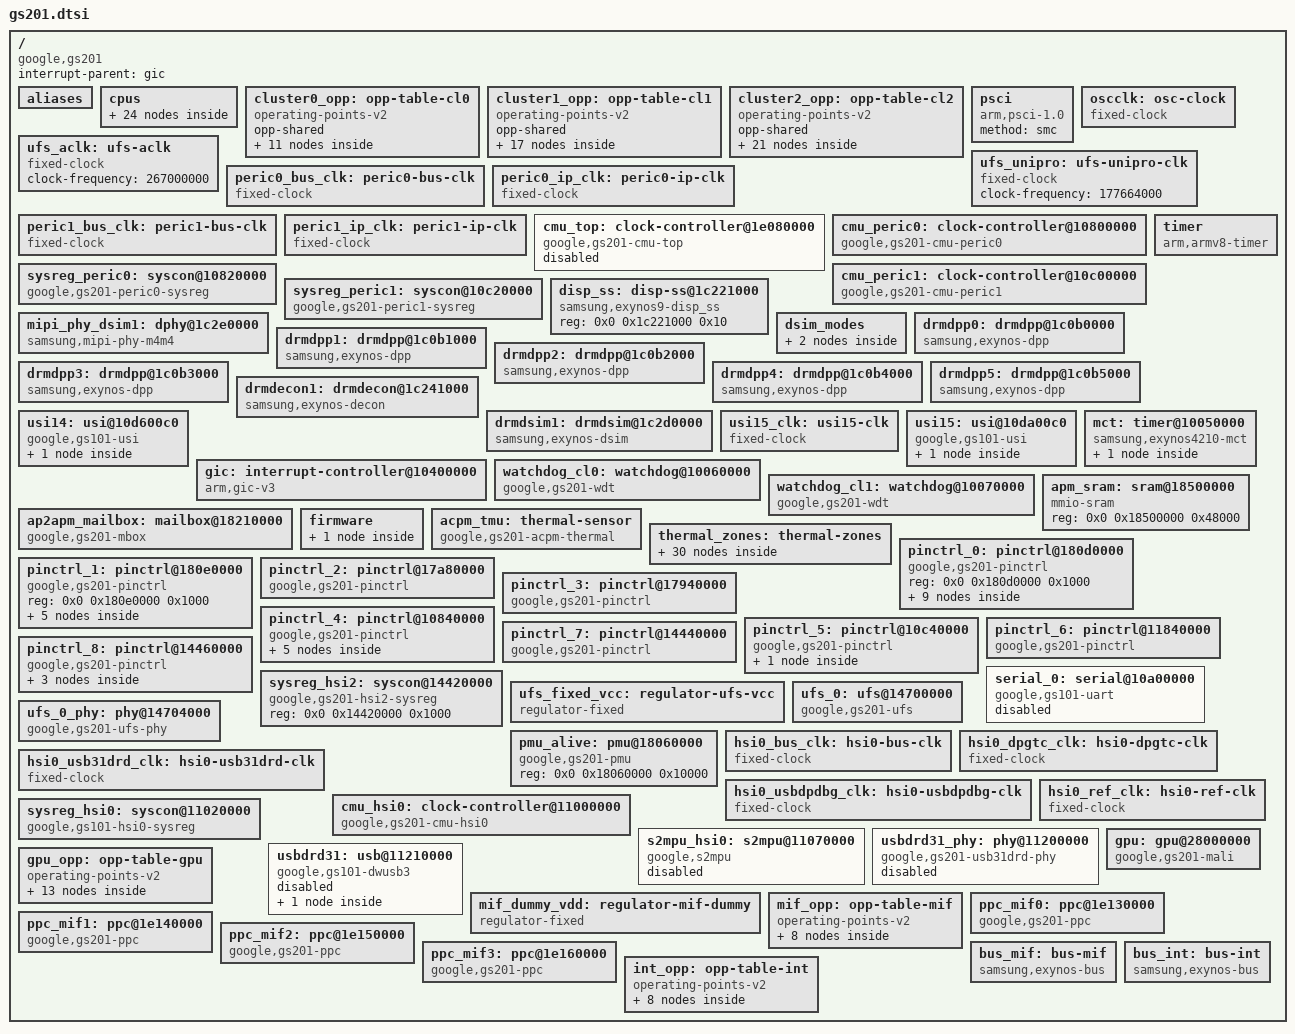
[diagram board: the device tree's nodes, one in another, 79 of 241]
// SPDX-License-Identifier: GPL-2.0-only
/*
 * Google GS201 (Tensor G2) SoC device tree source
 *
 * Copyright 2026 Google LLC
 *
 * Two non-obvious things about gs201:
 *
 * 1. BL31 firewalls EL1 CMU access UNLESS the kernel boots with
 *    `kvm-arm.mode=protected` (Makefile sets this). With pKVM disabled,
 *    direct readl of CMU_TOP @ 0x1e080000 aborts with synchronous external
 *    abort code 0x96000010. See memory/project_pkvm_cmu_unlock.md.
 *
 * 2. Even with CMU access unlocked, mainline `clk-gs101.c` is not
 *    register-layout compatible with gs201: many CMU_TOP and CMU_HSI2
 *    register offsets differ from gs101 (AOSP cal-if `cmucal-sfr.c` has
 *    the gs201-correct map; e.g. SHARED0_DIV4 is at 0x1930 on gs201 vs
 *    0x1908 on gs101, HSI2_BUS/MMC_CARD are swapped, etc.). Until a
 *    proper gs201 clock driver exists, UFS/peripheral clocks stay on
 *    fixed-rate stubs that report the bootloader-programmed rates.
 *    Hardware is already running at the right rate; the kernel just
 *    can't reprogram it without the correct offsets.
 */

#include <dt-bindings/clock/google,gs101.h>
#include <dt-bindings/clock/google,gs201-acpm.h>
#include <dt-bindings/gpio/gpio.h>
#include <dt-bindings/soc/samsung,exynos-usi.h>
#include <dt-bindings/interrupt-controller/arm-gic.h>
#include <dt-bindings/thermal/thermal.h>

/ {
	compatible = "google,gs201";
	interrupt-parent = <&gic>;
	#address-cells = <2>;
	#size-cells = <1>;

	aliases {
		pinctrl0 = &pinctrl_0;
		pinctrl1 = &pinctrl_1;
		pinctrl2 = &pinctrl_2;
		pinctrl3 = &pinctrl_3;
		pinctrl4 = &pinctrl_4;
		pinctrl5 = &pinctrl_5;
		pinctrl6 = &pinctrl_6;
		pinctrl7 = &pinctrl_7;
		pinctrl8 = &pinctrl_8;
		serial0  = &serial_0;
	};

	/* ------------------------------------------------------------------ */
	/* CPU topology                                                         */
	/* ------------------------------------------------------------------ */

	cpus {
		#address-cells = <2>;
		#size-cells = <0>;

		cpu-map {
			cluster0 {
				core0 { cpu = <&cpu0>; };
				core1 { cpu = <&cpu1>; };
				core2 { cpu = <&cpu2>; };
				core3 { cpu = <&cpu3>; };
			};
			cluster1 {
				core0 { cpu = <&cpu4>; };
				core1 { cpu = <&cpu5>; };
			};
			cluster2 {
				core0 { cpu = <&cpu6>; };
				core1 { cpu = <&cpu7>; };
			};
		};

		/* cluster0: ANANKE (Cortex-A55 derivative) */
		cpu0: cpu@0 {
			device_type = "cpu";
			compatible = "arm,cortex-a55";
			reg = <0x0 0x0000>;
			enable-method = "psci";
			cpu-idle-states = <&ananke_cpu_sleep>;
			capacity-dmips-mhz = <250>;
			dynamic-power-coefficient = <89>;
			operating-points-v2 = <&cluster0_opp>;
			clocks = <&acpm_ipc GS201_CLK_ACPM_DVFS_CPUCL0>;
			#cooling-cells = <2>;
		};
		cpu1: cpu@100 {
			device_type = "cpu";
			compatible = "arm,cortex-a55";
			reg = <0x0 0x0100>;
			enable-method = "psci";
			cpu-idle-states = <&ananke_cpu_sleep>;
			capacity-dmips-mhz = <250>;
			dynamic-power-coefficient = <89>;
			operating-points-v2 = <&cluster0_opp>;
			clocks = <&acpm_ipc GS201_CLK_ACPM_DVFS_CPUCL0>;
		};
		cpu2: cpu@200 {
			device_type = "cpu";
			compatible = "arm,cortex-a55";
			reg = <0x0 0x0200>;
			enable-method = "psci";
			cpu-idle-states = <&ananke_cpu_sleep>;
			capacity-dmips-mhz = <250>;
			dynamic-power-coefficient = <89>;
			operating-points-v2 = <&cluster0_opp>;
			clocks = <&acpm_ipc GS201_CLK_ACPM_DVFS_CPUCL0>;
		};
		cpu3: cpu@300 {
			device_type = "cpu";
			compatible = "arm,cortex-a55";
			reg = <0x0 0x0300>;
			enable-method = "psci";
			cpu-idle-states = <&ananke_cpu_sleep>;
			capacity-dmips-mhz = <250>;
			dynamic-power-coefficient = <89>;
			operating-points-v2 = <&cluster0_opp>;
			clocks = <&acpm_ipc GS201_CLK_ACPM_DVFS_CPUCL0>;
		};

		/* cluster1: HERCULES (Cortex-A78 derivative) */
		cpu4: cpu@400 {
			device_type = "cpu";
			compatible = "arm,cortex-a78";
			reg = <0x0 0x0400>;
			enable-method = "psci";
			cpu-idle-states = <&hercules_cpu_sleep>;
			capacity-dmips-mhz = <927>;
			dynamic-power-coefficient = <513>;
			operating-points-v2 = <&cluster1_opp>;
			clocks = <&acpm_ipc GS201_CLK_ACPM_DVFS_CPUCL1>;
			#cooling-cells = <2>;
		};
		cpu5: cpu@500 {
			device_type = "cpu";
			compatible = "arm,cortex-a78";
			reg = <0x0 0x0500>;
			enable-method = "psci";
			cpu-idle-states = <&hercules_cpu_sleep>;
			capacity-dmips-mhz = <927>;
			dynamic-power-coefficient = <513>;
			operating-points-v2 = <&cluster1_opp>;
			clocks = <&acpm_ipc GS201_CLK_ACPM_DVFS_CPUCL1>;
		};

		/* cluster2: HERA (Cortex-X1 derivative) */
		cpu6: cpu@600 {
			device_type = "cpu";
			compatible = "arm,cortex-x1";
			reg = <0x0 0x0600>;
			enable-method = "psci";
			cpu-idle-states = <&hera_cpu_sleep>;
			capacity-dmips-mhz = <1024>;
			dynamic-power-coefficient = <757>;
			operating-points-v2 = <&cluster2_opp>;
			clocks = <&acpm_ipc GS201_CLK_ACPM_DVFS_CPUCL2>;
			#cooling-cells = <2>;
		};
		cpu7: cpu@700 {
			device_type = "cpu";
			compatible = "arm,cortex-x1";
			reg = <0x0 0x0700>;
			enable-method = "psci";
			cpu-idle-states = <&hera_cpu_sleep>;
			capacity-dmips-mhz = <1024>;
			dynamic-power-coefficient = <757>;
			operating-points-v2 = <&cluster2_opp>;
			clocks = <&acpm_ipc GS201_CLK_ACPM_DVFS_CPUCL2>;
		};

		idle-states {
			entry-method = "arm,psci";

			ananke_cpu_sleep: ananke-cpu-sleep {
				compatible = "arm,idle-state";
				idle-state-name = "c2";
				arm,psci-suspend-param = <0x0010000>;
				entry-latency-us = <70>;
				exit-latency-us = <160>;
				min-residency-us = <2000>;
			};

			hercules_cpu_sleep: hercules-cpu-sleep {
				compatible = "arm,idle-state";
				idle-state-name = "c2";
				arm,psci-suspend-param = <0x0010000>;
				entry-latency-us = <150>;
				exit-latency-us = <190>;
				min-residency-us = <2500>;
			};

			hera_cpu_sleep: hera-cpu-sleep {
				compatible = "arm,idle-state";
				idle-state-name = "c2";
				arm,psci-suspend-param = <0x0010000>;
				entry-latency-us = <235>;
				exit-latency-us = <220>;
				min-residency-us = <3500>;
			};
		};
	};

	/* CPU OPP tables — frequencies sourced from Android DVFS tables */
	cluster0_opp: opp-table-cl0 {
		compatible = "operating-points-v2";
		opp-shared;
		opp-300000000  { opp-hz = /bits/ 64 <300000000>; opp-microvolt = <600000>; };
		opp-574000000  { opp-hz = /bits/ 64 <574000000>; opp-microvolt = <644000>; };
		opp-738000000  { opp-hz = /bits/ 64 <738000000>; opp-microvolt = <671000>; };
		opp-930000000  { opp-hz = /bits/ 64 <930000000>; opp-microvolt = <702000>; };
		opp-1066000000 { opp-hz = /bits/ 64 <1066000000>; opp-microvolt = <724000>; };
		opp-1197000000 { opp-hz = /bits/ 64 <1197000000>; opp-microvolt = <745000>; };
		opp-1328000000 { opp-hz = /bits/ 64 <1328000000>; opp-microvolt = <767000>; };
		opp-1459000000 { opp-hz = /bits/ 64 <1459000000>; opp-microvolt = <788000>; };
		opp-1574000000 { opp-hz = /bits/ 64 <1574000000>; opp-microvolt = <807000>; };
		opp-1746000000 { opp-hz = /bits/ 64 <1746000000>; opp-microvolt = <835000>; };
		opp-1836000000 { opp-hz = /bits/ 64 <1836000000>; opp-microvolt = <850000>; };
	};

	cluster1_opp: opp-table-cl1 {
		compatible = "operating-points-v2";
		opp-shared;
		opp-400000000  { opp-hz = /bits/ 64 <400000000>; opp-microvolt = <600000>; };
		opp-553000000  { opp-hz = /bits/ 64 <553000000>; opp-microvolt = <631000>; };
		opp-696000000  { opp-hz = /bits/ 64 <696000000>; opp-microvolt = <660000>; };
		opp-852000000  { opp-hz = /bits/ 64 <852000000>; opp-microvolt = <692000>; };
		opp-984000000  { opp-hz = /bits/ 64 <984000000>; opp-microvolt = <719000>; };
		opp-1106000000 { opp-hz = /bits/ 64 <1106000000>; opp-microvolt = <744000>; };
		opp-1197000000 { opp-hz = /bits/ 64 <1197000000>; opp-microvolt = <763000>; };
		opp-1328000000 { opp-hz = /bits/ 64 <1328000000>; opp-microvolt = <790000>; };
		opp-1459000000 { opp-hz = /bits/ 64 <1459000000>; opp-microvolt = <817000>; };
		opp-1606000000 { opp-hz = /bits/ 64 <1606000000>; opp-microvolt = <847000>; };
		opp-1737000000 { opp-hz = /bits/ 64 <1737000000>; opp-microvolt = <874000>; };
		opp-1836000000 { opp-hz = /bits/ 64 <1836000000>; opp-microvolt = <894000>; };
		opp-1950000000 { opp-hz = /bits/ 64 <1950000000>; opp-microvolt = <918000>; };
		opp-2048000000 { opp-hz = /bits/ 64 <2048000000>; opp-microvolt = <938000>; };
		opp-2130000000 { opp-hz = /bits/ 64 <2130000000>; opp-microvolt = <955000>; };
		opp-2253000000 { opp-hz = /bits/ 64 <2253000000>; opp-microvolt = <980000>; };
		opp-2348000000 { opp-hz = /bits/ 64 <2348000000>; opp-microvolt = <1000000>; };
	};

	cluster2_opp: opp-table-cl2 {
		compatible = "operating-points-v2";
		opp-shared;
		opp-500000000  { opp-hz = /bits/ 64 <500000000>; opp-microvolt = <650000>; };
		opp-851000000  { opp-hz = /bits/ 64 <851000000>; opp-microvolt = <709000>; };
		opp-955000000  { opp-hz = /bits/ 64 <955000000>; opp-microvolt = <727000>; };
		opp-1098000000 { opp-hz = /bits/ 64 <1098000000>; opp-microvolt = <751000>; };
		opp-1197000000 { opp-hz = /bits/ 64 <1197000000>; opp-microvolt = <768000>; };
		opp-1328000000 { opp-hz = /bits/ 64 <1328000000>; opp-microvolt = <790000>; };
		opp-1459000000 { opp-hz = /bits/ 64 <1459000000>; opp-microvolt = <813000>; };
		opp-1557000000 { opp-hz = /bits/ 64 <1557000000>; opp-microvolt = <829000>; };
		opp-1647000000 { opp-hz = /bits/ 64 <1647000000>; opp-microvolt = <845000>; };
		opp-1745000000 { opp-hz = /bits/ 64 <1745000000>; opp-microvolt = <861000>; };
		opp-1836000000 { opp-hz = /bits/ 64 <1836000000>; opp-microvolt = <877000>; };
		opp-1950000000 { opp-hz = /bits/ 64 <1950000000>; opp-microvolt = <896000>; };
		opp-2048000000 { opp-hz = /bits/ 64 <2048000000>; opp-microvolt = <913000>; };
		opp-2130000000 { opp-hz = /bits/ 64 <2130000000>; opp-microvolt = <927000>; };
		opp-2253000000 { opp-hz = /bits/ 64 <2253000000>; opp-microvolt = <948000>; };
		opp-2348000000 { opp-hz = /bits/ 64 <2348000000>; opp-microvolt = <964000>; };
		opp-2500000000 { opp-hz = /bits/ 64 <2500000000>; opp-microvolt = <990000>; };
		opp-2630000000 { opp-hz = /bits/ 64 <2630000000>; opp-microvolt = <1012000>; };
		opp-2704000000 { opp-hz = /bits/ 64 <2704000000>; opp-microvolt = <1025000>; };
		opp-2802000000 { opp-hz = /bits/ 64 <2802000000>; opp-microvolt = <1041000>; };
		opp-2850000000 { opp-hz = /bits/ 64 <2850000000>; opp-microvolt = <1050000>; };
	};

	/* ------------------------------------------------------------------ */
	/* System                                                               */
	/* ------------------------------------------------------------------ */

	psci {
		compatible = "arm,psci-1.0";
		method = "smc";
	};

	/* 24.576 MHz crystal — primary oscillator for the SoC */
	oscclk: osc-clock {
		compatible = "fixed-clock";
		#clock-cells = <0>;
		clock-frequency = <24576000>;
		clock-output-names = "oscclk";
	};

	/*
	 * Fixed-rate stubs for UFS — see top-of-file note about gs201
	 * CMU register offsets being incompatible with mainline clk-gs101.
	 * Rates back-computed from raw CMU_TOP register reads on a real
	 * boot using gs201-correct offsets (see git history for the probe):
	 *
	 *   PLL_CON3_PLL_SHARED0 = 0xa15b0400
	 *     → M=347, P=4, S=0 → 24.576MHz * 347/4/1 = 2,131,968,000 Hz
	 *   shared0_div4 = 2131968000 / 4 = 532,992,000 Hz
	 *   MUX_HSI2_UFS_EMBD = 1 (selects shared0_div4)
	 *   DIV_HSI2_UFS_EMBD = 2 (divides by 3)
	 *     → mclk_rate = 532992000 / 3 = 177,664,000 Hz
	 *
	 * ufs_aclk's actual rate would come from HSI2_NOC (gs201's "BUS"
	 * divider, at offset 0x189c — different from gs101's 0x1898 which
	 * holds MMC_CARD on gs201). Not yet measured; leaving at the
	 * driver's PCLK_AVAIL_MAX as a known-in-range value.
	 */
	ufs_aclk: ufs-aclk {
		compatible = "fixed-clock";
		#clock-cells = <0>;
		clock-frequency = <267000000>;
	};

	ufs_unipro: ufs-unipro-clk {
		compatible = "fixed-clock";
		#clock-cells = <0>;
		clock-frequency = <177664000>;
	};

	/*
	 * cmu_peric0 input-clock stubs. The mainline clk-gs101.c CMU_TOP
	 * driver isn't validated for gs201 yet (cmu_top is left disabled
	 * below), so cmu_peric0 can't get its bus/ip parents from there.
	 * Provide them as fixed-clocks at the rates AOSP cal-if reports
	 * for felix at runtime:
	 *
	 *   peric0_bus_clk @ 200 MHz — VDOUT_CMU_PERIC0_NOC target rate
	 *                              from cmucal-vclk.c.
	 *   peric0_ip_clk  @ 400 MHz — back-derived: AOSP says
	 *                              VCLK_DIV_CLK_PERIC0_USI0_UART
	 *                              = 200 MHz with the cmu_peric0
	 *                              divider at value 1 (divide by 2),
	 *                              so the user-mux output (= IP) is
	 *                              400 MHz.
	 *
	 * If samsung_tty later reports a base_baud that doesn't match
	 * 115200 cleanly, the actual IP rate is the first thing to recheck
	 * (read the cmu_peric0 USI0_UART divider register at offset 0x1808
	 * over /dev/mem, divide 400 MHz by (DIV+1) and compare to AOSP).
	 */
	peric0_bus_clk: peric0-bus-clk {
		compatible = "fixed-clock";
		#clock-cells = <0>;
		clock-frequency = <200000000>;
		clock-output-names = "peric0_bus";
	};

	peric0_ip_clk: peric0-ip-clk {
		compatible = "fixed-clock";
		#clock-cells = <0>;
		clock-frequency = <400000000>;
		clock-output-names = "peric0_ip";
	};

	/*
	 * PERIC1 bus/ip stubs — same rationale as peric0 above. cmu_top is
	 * disabled (SError on gs201's divider map), so cmu_peric1 can't pull
	 * its bus/ip parents from CLK_DOUT_CMU_PERIC1_* there; feed it the
	 * bootloader-programmed fixed rates instead. PERIC1 hosts USI14 (the
	 * felix MAX77759 PMIC/charger i2c bus, hsi2c@10d60000).
	 */
	peric1_bus_clk: peric1-bus-clk {
		compatible = "fixed-clock";
		#clock-cells = <0>;
		clock-frequency = <200000000>;
		clock-output-names = "peric1_bus";
	};

	peric1_ip_clk: peric1-ip-clk {
		compatible = "fixed-clock";
		#clock-cells = <0>;
		clock-frequency = <400000000>;
		clock-output-names = "peric1_ip";
	};

	/* ------------------------------------------------------------------ */
	/* CMU clock controllers                                                */
	/* ------------------------------------------------------------------ */

	/*
	 * Top-level CMU. clk-gs101.c declares `google,gs201-cmu-top` and uses
	 * the gs201-specific `top_cmu_info_gs201` rate table (gs201's PLL/MUX
	 * register offsets aren't byte-identical to gs101's — see gs201.dtsi
	 * top-of-file note). Probed via late_initcall so the EL1 reads happen
	 * after pKVM unlocks BL31's CMU firewall (project_pkvm_cmu_unlock.md).
	 */
	cmu_top: clock-controller@1e080000 {
		compatible = "google,gs201-cmu-top";
		reg = <0x0 0x1e080000 0x10000>;
		#clock-cells = <1>;
		clocks = <&oscclk>;
		clock-names = "oscclk";
		/*
		 * Disabled. Mainline clk-gs101.c advertises a
		 * `google,gs201-cmu-top` compat but reuses the gs101 register
		 * map. Empirically (2026-05-03 boot test) that map has at
		 * least one divider register at an offset gs201 doesn't
		 * implement: probe panics with `Asynchronous SError Interrupt`
		 * inside `clk_divider_recalc_rate` shortly after a benign
		 * "Unable to get CMU sysreg" warning. Re-enabling requires
		 * either a gs201-specific divider/mux table in clk-gs101.c
		 * (cross-referenced against AOSP cal-if cmucal-sfr.c offsets)
		 * or a brand new clk-gs201.c sibling driver.
		 */
		status = "disabled";
	};

	/*
	 * PERIC0 CMU — supplies clocks to USI0 UART (ttySAC0), I2C/SPI/I3C
	 * masters in the PERIC0 domain, GPIO/sysreg PCLKs, etc. Driver shares
	 * `peric0_cmu_info` with the gs101 variant; if a future investigation
	 * shows gs201's PERIC0 register layout differs from gs101's, this
	 * node will need to fall back to a fixed-clock stub for clk_uart_baud0
	 * until a gs201-specific rate table is written.
	 */
	cmu_peric0: clock-controller@10800000 {
		compatible = "google,gs201-cmu-peric0";
		reg = <0x0 0x10800000 0x10000>;
		#clock-cells = <1>;
		clocks = <&oscclk>, <&peric0_bus_clk>, <&peric0_ip_clk>;
		clock-names = "oscclk", "bus", "ip";
		samsung,sysreg = <&sysreg_peric0>;
	};

	sysreg_peric0: syscon@10820000 {
		compatible = "google,gs201-peric0-sysreg", "syscon";
		reg = <0x0 0x10820000 0x10000>;
		clocks = <&cmu_peric0 CLK_GOUT_PERIC0_SYSREG_PERIC0_PCLK>;
	};

	/*
	 * PERIC1 CMU + sysreg — clk-gs101.c advertises `google,gs201-cmu-peric1`
	 * and has the full PERIC1 mux/div/gate table. Same fixed-stub parent
	 * trick as cmu_peric0 (cmu_top is disabled). Supplies USI14 (hsi2c@10d60000).
	 */
	cmu_peric1: clock-controller@10c00000 {
		compatible = "google,gs201-cmu-peric1";
		reg = <0x0 0x10c00000 0x10000>;
		#clock-cells = <1>;
		clocks = <&oscclk>, <&peric1_bus_clk>, <&peric1_ip_clk>;
		clock-names = "oscclk", "bus", "ip";
		samsung,sysreg = <&sysreg_peric1>;
		/*
		 * USI13 (hsi2c@10d60000) clock fix. Its "_usi_user" mux selects
		 * { oscclk, dout_cmu_peric1_ip }; the latter comes from cmu_top,
		 * which is disabled on gs201, so the mux sits at rate 0 and the
		 * hsi2c driver can't bind. Unlike PERIC0/UART, clk-gs101.c has no
		 * gs201 stub variant for the PERIC1 USIs, so re-parent the mux to
		 * oscclk (24.576 MHz — plenty for 100/400 kHz i2c) here.
		 */
		assigned-clocks = <&cmu_peric1 CLK_MOUT_PERIC1_USI13_USI_USER>;
		assigned-clock-parents = <&oscclk>;
	};

	sysreg_peric1: syscon@10c20000 {
		compatible = "google,gs201-peric1-sysreg", "syscon";
		reg = <0x0 0x10c20000 0x10000>;
		clocks = <&cmu_peric1 CLK_GOUT_PERIC1_SYSREG_PERIC1_PCLK>;
	};

	/*
	 * Display (DPU) — OUTER/cover panel path DECON1 -> DSIM1 -> ea8182-f10.
	 * Drives the grafted AOSP samsung DRM (drivers/gpu/drm/samsung-felix).
	 * decon/dsim clocks + power are managed by the CAL layer via ACPM/CMU
	 * (no DT clock phandles, no genpd) — same "bootloader gate + CAL" model
	 * the gs201 fuel-gauge/USI stubs use. sysmmu_dpu is absent on mainline
	 * so GEM uses CMA (no iommus). decon1/dsim1 stay status="disabled" until
	 * the ACPM/EL3 pd_dpu power-on and the DSIM D-PHY shim land — probing
	 * DECON MMIO on an unpowered domain external-aborts (headless hang).
	 */
	disp_ss: disp-ss@1c221000 {
		compatible = "samsung,exynos9-disp_ss";
		reg = <0x0 0x1c221000 0x10>;
		reg-names = "sys";
	};

	mipi_phy_dsim1: dphy@1c2e0000 {
		compatible = "samsung,mipi-phy-m4m4";
		isolation = <0x3eb8>;
		owner = <0>;		/* 0: DSI, 1: CSI */
		#phy-cells = <1>;
	};

	/*
	 * DSI PLL params keyed by mode-name. dsim_mode_valid() rejects any
	 * display mode (MODE_NOMODE) for which dsim_get_clock_mode() finds no
	 * matching entry here, so without this node the ea8182 1080x2092 modes
	 * are pruned and no modeset is possible. pmsk/hs-clk/esc-clk are the
	 * AOSP felix values (gs101-display-timing.dtsi 1080x2092). The driver
	 * prefix-matches "1080x2092" so this one entry covers @60 and @120.
	 */
	dsim_modes: dsim_modes {
		dsim-modes {
			mode_1080x2092 {
				mode-name = "1080x2092";
				pmsk = <
					0x2 0xEE 0x3 0xA155 /* p m s k */
					>;
				hs-clk = <730>;
				esc-clk = <20>;
			};
		};
	};

	drmdpp0: drmdpp@1c0b0000 {	/* L0 */
		compatible = "samsung,exynos-dpp";
		reg = <0x0 0x1c0b0000 0x1000>, <0x0 0x1c0d0000 0x1000>, <0x0 0x1c0e0000 0x1000>;
		reg-names = "dma", "dpp", "hdr";
		interrupts = <GIC_SPI 262 IRQ_TYPE_LEVEL_HIGH>, <GIC_SPI 271 IRQ_TYPE_LEVEL_HIGH>;
		interrupt-names = "dma", "dpp";
		attr = <0x50047>;
		port = <0>;
		scale_down = <1>;
		scale_up = <1>;
		dpp,id = <0>;
	};
	drmdpp1: drmdpp@1c0b1000 {	/* L1 */
		compatible = "samsung,exynos-dpp";
		reg = <0x0 0x1c0b1000 0x1000>, <0x0 0x1c0d1000 0x1000>, <0x0 0x1c0e1000 0x1000>;
		reg-names = "dma", "dpp", "hdr";
		interrupts = <GIC_SPI 263 IRQ_TYPE_LEVEL_HIGH>, <GIC_SPI 272 IRQ_TYPE_LEVEL_HIGH>;
		interrupt-names = "dma", "dpp";
		attr = <0x50047>;
		port = <0>;
		scale_down = <1>;
		scale_up = <1>;
		dpp,id = <1>;
	};
	drmdpp2: drmdpp@1c0b2000 {	/* L2 */
		compatible = "samsung,exynos-dpp";
		reg = <0x0 0x1c0b2000 0x1000>, <0x0 0x1c0d2000 0x1000>, <0x0 0x1c0e2000 0x1000>;
		reg-names = "dma", "dpp", "hdr";
		interrupts = <GIC_SPI 264 IRQ_TYPE_LEVEL_HIGH>, <GIC_SPI 273 IRQ_TYPE_LEVEL_HIGH>;
		interrupt-names = "dma", "dpp";
		attr = <0x50047>;
		port = <1>;
		scale_down = <1>;
		scale_up = <1>;
		dpp,id = <2>;
	};
	drmdpp3: drmdpp@1c0b3000 {	/* L3 */
		compatible = "samsung,exynos-dpp";
		reg = <0x0 0x1c0b3000 0x1000>, <0x0 0x1c0d3000 0x1000>, <0x0 0x1c0e3000 0x1000>;
		reg-names = "dma", "dpp", "hdr";
		interrupts = <GIC_SPI 265 IRQ_TYPE_LEVEL_HIGH>, <GIC_SPI 274 IRQ_TYPE_LEVEL_HIGH>;
		interrupt-names = "dma", "dpp";
		attr = <0x50047>;
		port = <1>;
		scale_down = <1>;
		scale_up = <1>;
		dpp,id = <3>;
	};
	drmdpp4: drmdpp@1c0b4000 {	/* L4 */
		compatible = "samsung,exynos-dpp";
		reg = <0x0 0x1c0b4000 0x1000>, <0x0 0x1c0d4000 0x1000>, <0x0 0x1c0e4000 0x1000>;
		reg-names = "dma", "dpp", "hdr";
		interrupts = <GIC_SPI 266 IRQ_TYPE_LEVEL_HIGH>, <GIC_SPI 275 IRQ_TYPE_LEVEL_HIGH>;
		interrupt-names = "dma", "dpp";
		attr = <0x50047>;
		port = <0>;
		scale_down = <1>;
		scale_up = <1>;
		dpp,id = <4>;
	};
	drmdpp5: drmdpp@1c0b5000 {	/* L5 */
		compatible = "samsung,exynos-dpp";
		reg = <0x0 0x1c0b5000 0x1000>, <0x0 0x1c0d5000 0x1000>, <0x0 0x1c0e5000 0x1000>;
		reg-names = "dma", "dpp", "hdr";
		interrupts = <GIC_SPI 267 IRQ_TYPE_LEVEL_HIGH>, <GIC_SPI 276 IRQ_TYPE_LEVEL_HIGH>;
		interrupt-names = "dma", "dpp";
		attr = <0x50047>;
		port = <1>;
		scale_down = <1>;
		scale_up = <1>;
		dpp,id = <5>;
	};

	drmdecon1: drmdecon@1c241000 {
		status = "okay";
		compatible = "samsung,exynos-decon";
		reg = <0x0 0x1c241000 0x6000>,	/* MAIN */
		      <0x0 0x1c250000 0x6000>,	/* WIN */
		      <0x0 0x1c260000 0x10000>,	/* SUB */
		      <0x0 0x1c280000 0x6000>,	/* WINCON */
		      <0x0 0x1c2b0000 0xf000>,	/* DQE1 */
		      <0x0 0x1c0bf000 0x1000>;	/* CGC_DMA */
		reg-names = "main", "win", "sub", "wincon", "dqe", "cgc-dma";
		decon,id = <1>;
		cgc-dma,id = <10>;
		interrupts = <GIC_SPI 246 IRQ_TYPE_LEVEL_HIGH>,		/* frame_start */
			     <GIC_SPI 245 IRQ_TYPE_LEVEL_HIGH>,		/* frame_done */
			     <GIC_SPI 244 IRQ_TYPE_LEVEL_HIGH>,		/* extra */
			     <GIC_SPI 243 IRQ_TYPE_LEVEL_HIGH>,		/* dimming_start */
			     <GIC_SPI 242 IRQ_TYPE_LEVEL_HIGH>,		/* dimming_end */
			     <GIC_SPI 261 IRQ_TYPE_LEVEL_HIGH>;		/* cgc-dma */
		interrupt-names = "frame_start", "frame_done", "extra",
				  "dimming_start", "dimming_end", "cgc-dma";
		max_win = <6>;
		ppc = <2>;
		ppc_rotator = <4>;
		ppc_scaler = <2>;
		delay_comp = <4>;
		delay_scaler = <3>;
		bus_width = <16>;
		bus_util = <65>;
		rot_util = <60>;
		dfs_lv_cnt = <7>;
		dfs_lv = <664000 533000 465000 400000 310000 267000 134000>;
		rd_en = <1>;
		rd_hi_thres = <0x800>;
		rd_lo_thres = <0x400>;
		rd_wait_cycle = <0x11>;
		dta_en = <1>;
		dta_hi_thres = <0x3200>;
		dta_lo_thres = <0x600>;
		dpps = <&drmdpp0 &drmdpp1 &drmdpp2 &drmdpp3 &drmdpp4 &drmdpp5>;
		/* DSI0(0x1), DSI1(0x2), VIDI(0x8) */
		connector = <0x1 0x2 0x8>;
	};

	drmdsim1: drmdsim@1c2d0000 {
		status = "okay";
		compatible = "samsung,exynos-dsim";
		reg = <0x0 0x1c2d0000 0x300>,	/* DSI */
		      <0x0 0x1c2e0900 0x700>,	/* M4M4S0 PHY */
		      <0x0 0x1c2e0000 0x100>;	/* M4M4S0 PHY BIAS */
		reg-names = "dsi", "dphy", "dphy-extra";
		dsim,id = <1>;
		interrupts = <GIC_SPI 251 IRQ_TYPE_LEVEL_HIGH>;
		interrupt-names = "dsim";
		phys = <&mipi_phy_dsim1 0>;
		phy-names = "dsim_dphy";
		dsim_mode = <&dsim_modes>;
		te_from = <1>;
		/* outer-panel TE (EINT) on gpp0-4; resolved via gpiod in the
		 * dsim driver so the decon takes HW command-mode trigger off
		 * the panel's tearing-effect line instead of sw_trigger. */
		te-gpios = <&gpp0 4 0>;
		pinctrl-names = "hw_te_on", "hw_te_off";
		pinctrl-0 = <&disp_te_sec_on>;
		pinctrl-1 = <&disp_te_sec_off>;
		#address-cells = <1>;
		#size-cells = <0>;
	};

	/*
	 * USI14 (PERIC1) in HS-I2C mode — the felix MAX77759 PMIC/charger/
	 * fuel-gauge/TCPC live on this bus (pmic@66, chrg@69, fg@36, tcpc@25).
	 * Same SoC block as gs101's usi13/hsi2c@10d60000; gs201 differs only in
	 * the GIC line (695) and the 2-cell soc addressing. Bring it up so we can
	 * reach the MAX77759 charger and enable its OTG VBUS boost (host-mode
	 * dongle networking).
	 */
	usi14: usi@10d600c0 {
		compatible = "google,gs101-usi", "samsung,exynos850-usi";
		reg = <0x0 0x10d600c0 0x20>;
		ranges;
		#address-cells = <2>;
		#size-cells = <1>;
		clocks = <&cmu_peric1 CLK_GOUT_PERIC1_PERIC1_TOP0_PCLK_6>,
			 <&cmu_peric1 CLK_GOUT_PERIC1_PERIC1_TOP0_IPCLK_6>;
		clock-names = "pclk", "ipclk";
		samsung,sysreg = <&sysreg_peric1 0x1014>;
		samsung,mode = <USI_MODE_I2C>;
		status = "okay";

		hsi2c14: i2c@10d60000 {
			compatible = "google,gs101-hsi2c",
				     "samsung,exynosautov9-hsi2c";
			reg = <0x0 0x10d60000 0xc0>;
			#address-cells = <1>;
			#size-cells = <0>;
			clocks = <&cmu_peric1 CLK_GOUT_PERIC1_PERIC1_TOP0_IPCLK_6>,
				 <&cmu_peric1 CLK_GOUT_PERIC1_PERIC1_TOP0_PCLK_6>;
			clock-names = "hsi2c", "hsi2c_pclk";
			interrupts = <GIC_SPI 695 IRQ_TYPE_LEVEL_HIGH>;
			/*
			 * No pinctrl-0: the gpp25-0/1 SDA/SCL pins are already in
			 * i2c alt-function from the bootloader (it talks to the
			 * MAX77759 on this bus), same as uart0 above. Declaring an
			 * hsi2c14_bus group would need all 26 gpp banks defined in
			 * order (samsung pinctrl matches bank subnodes positionally),
			 * which isn't worth it when the POR state already works.
			 */
			status = "okay";
		};
	};

		/*
		 * USI15 (PERIC1) in HS-I2C mode @ 10da0000 — felix's SECONDARY
		 * fuel gauge (the larger fold pack: max1720x@36 + 0x0b nvram) lives
		 * here, alongside the CS40L26 haptics, wireless charger and an
		 * EEPROM (not wired). This USI does NOT exist on gs101, so
		 * clk-gs101.c has no gs201 USI15 mux/gate model — feed the block a
		 * fixed ipclk/pclk stub instead. The bootloader leaves the CMU gate
		 * (GATE_PERIC1_TOP0_USI15_USI) enabled to reach the gauge at boot,
		 * and the cmdline's clk_ignore_unused keeps it that way, so the
		 * block stays clocked. GIC line 696, sysreg USI mode reg at peric1
		 * +0x18 (vs +0x14 for USI13), SDA/SCL on gpp24-0/1 (left in i2c
		 * alt-func by the bootloader, so no pinctrl-0).
		 */
		usi15_clk: usi15-clk {
			compatible = "fixed-clock";
			#clock-cells = <0>;
			clock-frequency = <200000000>;
			clock-output-names = "usi15_clk";
		};

		usi15: usi@10da00c0 {
			compatible = "google,gs101-usi", "samsung,exynos850-usi";
			reg = <0x0 0x10da00c0 0x20>;
			ranges;
			#address-cells = <2>;
			#size-cells = <1>;
			clocks = <&usi15_clk>, <&usi15_clk>;
			clock-names = "pclk", "ipclk";
			samsung,sysreg = <&sysreg_peric1 0x1018>;
			samsung,mode = <USI_MODE_I2C>;
			status = "okay";

			hsi2c15: i2c@10da0000 {
				compatible = "google,gs101-hsi2c",
					     "samsung,exynosautov9-hsi2c";
				reg = <0x0 0x10da0000 0xc0>;
				#address-cells = <1>;
				#size-cells = <0>;
				clocks = <&usi15_clk>, <&usi15_clk>;
				clock-names = "hsi2c", "hsi2c_pclk";
				interrupts = <GIC_SPI 696 IRQ_TYPE_LEVEL_HIGH>;
				status = "okay";
			};
		};

	/* ------------------------------------------------------------------ */
	/* Interrupt controller                                                 */
	/* ------------------------------------------------------------------ */

	gic: interrupt-controller@10400000 {
		compatible = "arm,gic-v3";
		#interrupt-cells = <3>;
		interrupt-controller;
		reg = <0x0 0x10400000 0x10000>,   /* GICD */
		      <0x0 0x10440000 0x100000>;  /* GICR × 8 */
		interrupts = <GIC_PPI 9 IRQ_TYPE_LEVEL_HIGH>;
	};

	/* ------------------------------------------------------------------ */
	/* Timers                                                               */
	/* ------------------------------------------------------------------ */

	timer {
		compatible = "arm,armv8-timer";
		interrupts = <GIC_PPI 13 (GIC_CPU_MASK_SIMPLE(8) | IRQ_TYPE_LEVEL_LOW)>,
			     <GIC_PPI 14 (GIC_CPU_MASK_SIMPLE(8) | IRQ_TYPE_LEVEL_LOW)>,
			     <GIC_PPI 11 (GIC_CPU_MASK_SIMPLE(8) | IRQ_TYPE_LEVEL_LOW)>,
			     <GIC_PPI 10 (GIC_CPU_MASK_SIMPLE(8) | IRQ_TYPE_LEVEL_LOW)>;
		clock-frequency = <24576000>;
	};

	mct: timer@10050000 {
		compatible = "samsung,exynos4210-mct";
		reg = <0x0 0x10050000 0x800>;
		interrupt-controller;
		#interrupt-cells = <1>;
		interrupt-parent = <&mct_map>;
		interrupts = <0>, <1>, <2>,  <3>,
			     <4>, <5>, <6>,  <7>,
			     <8>, <9>, <10>, <11>;
		clocks = <&oscclk>, <&oscclk>;
		clock-names = "fin_pll", "mct";

		mct_map: mct-map {
			#interrupt-cells = <1>;
			#address-cells = <0>;
			#size-cells = <0>;
			interrupt-map =
				<0  &gic 0 785 IRQ_TYPE_LEVEL_HIGH>,
				<1  &gic 0 786 IRQ_TYPE_LEVEL_HIGH>,
				<2  &gic 0 787 IRQ_TYPE_LEVEL_HIGH>,
				<3  &gic 0 788 IRQ_TYPE_LEVEL_HIGH>,
				<4  &gic 0 789 IRQ_TYPE_LEVEL_HIGH>,
				<5  &gic 0 790 IRQ_TYPE_LEVEL_HIGH>,
				<6  &gic 0 791 IRQ_TYPE_LEVEL_HIGH>,
				<7  &gic 0 792 IRQ_TYPE_LEVEL_HIGH>,
				<8  &gic 0 793 IRQ_TYPE_LEVEL_HIGH>,
				<9  &gic 0 794 IRQ_TYPE_LEVEL_HIGH>,
				<10 &gic 0 795 IRQ_TYPE_LEVEL_HIGH>,
				<11 &gic 0 796 IRQ_TYPE_LEVEL_HIGH>;
		};
	};

	/* ------------------------------------------------------------------ */
	/* Watchdog timers                                                      */
	/* ------------------------------------------------------------------ */

	watchdog_cl0: watchdog@10060000 {
		compatible = "google,gs201-wdt";
		reg = <0x0 0x10060000 0x100>;
		clocks = <&oscclk>;
		clock-names = "watchdog";
		interrupts = <GIC_SPI 797 IRQ_TYPE_LEVEL_HIGH>;
		samsung,syscon-phandle = <&pmu_alive>;
		samsung,cluster-index = <0>;
	};

	watchdog_cl1: watchdog@10070000 {
		compatible = "google,gs201-wdt";
		reg = <0x0 0x10070000 0x100>;
		clocks = <&oscclk>;
		clock-names = "watchdog";
		interrupts = <GIC_SPI 798 IRQ_TYPE_LEVEL_HIGH>;
		samsung,syscon-phandle = <&pmu_alive>;
		samsung,cluster-index = <1>;
	};

	/* ------------------------------------------------------------------ */
	/* ACPM — Always-on Power Management coprocessor                       */
	/* ------------------------------------------------------------------ */

	/*
	 * AP-to-APM mailbox — raises a doorbell interrupt to the ACPM
	 * coprocessor.  The ACPM IPC driver uses this via the mailbox
	 * framework.  "pclk" is the APM-domain peripheral clock; supply
	 * the oscclk stub until a GS201 ALIVE-CMU driver exists.
	 */
	ap2apm_mailbox: mailbox@18210000 {
		compatible = "google,gs201-mbox";
		reg = <0x0 0x18210000 0x1000>;
		clocks = <&oscclk>;
		clock-names = "pclk";
		interrupts = <GIC_SPI 78 IRQ_TYPE_LEVEL_HIGH>;
		#mbox-cells = <0>;
	};

	/*
	 * APM shared SRAM — 288 KiB window visible to both the AP and the
	 * ACPM coprocessor.  The ACPM IPC driver maps the channel descriptors
	 * and TX/RX buffers out of this region.
	 */
	apm_sram: sram@18500000 {
		compatible = "mmio-sram";
		reg = <0x0 0x18500000 0x48000>;
		#address-cells = <1>;
		#size-cells = <1>;
		ranges = <0 0x0 0x18500000 0x48000>;
	};

	firmware {
		/*
		 * ACPM IPC + DVFS clock provider.
		 * Exposes all DVFS-managed clocks (GPU, CPU clusters, MIF …)
		 * as a clock provider with #clock-cells = <1>.  Use the
		 * GS201_CLK_ACPM_DVFS_* constants from
		 * <dt-bindings/clock/google,gs201-acpm.h>.
		 */
		acpm_ipc: power-management {
			compatible = "google,gs201-acpm-ipc";
			#clock-cells = <1>;
			mboxes = <&ap2apm_mailbox>;
			shmem = <&apm_sram>;
		};
	};

	/*
	 * gs201 TMU is read over ACPM IPC (channel IPC_AP_TMU), not MMIO.
	 * The gs201_acpm_thermal driver registers these sensors; the cell in a
	 * thermal-zone's thermal-sensors phandle is the ACPM tz id:
	 *   0=BIG 1=MID 2=LITTLE 3=G3D 4=ISP 5=TPU 6=AUR 7=...
	 */
	acpm_tmu: thermal-sensor {
		compatible = "google,gs201-acpm-thermal";
		samsung,acpm-ipc = <&acpm_ipc>;
		samsung,tmu-channel = <9>;
		#thermal-sensor-cells = <1>;
	};

	thermal_zones: thermal-zones {
		/*
		 * Bring-up thermal management: the mainline port previously had
		 * no sensors at all, so the SoC heated unthrottled under load
		 * until a HW/PMIC cutoff hard-powered the device off. These
		 * zones give the thermal core temperatures to act on — passive
		 * trips throttle the matching CPU cluster / GPU DVFS, critical
		 * trips are a graceful-shutdown backstop below the HW cutoff.
		 */
		big-thermal {
			polling-delay-passive = <250>;
			polling-delay = <1000>;
			thermal-sensors = <&acpm_tmu 0>;
			sustainable-power = <2500>;
			trips {
				big_alert: alert {
					temperature = <90000>;
					hysteresis = <5000>;
					type = "passive";
				};
				big_crit: crit {
					temperature = <115000>;
					hysteresis = <0>;
					type = "critical";
				};
			};
			cooling-maps {
				map0 {
					trip = <&big_alert>;
					cooling-device = <&cpu6 THERMAL_NO_LIMIT THERMAL_NO_LIMIT>;
				};
			};
		};

		mid-thermal {
			polling-delay-passive = <250>;
			polling-delay = <1000>;
			thermal-sensors = <&acpm_tmu 1>;
			sustainable-power = <1500>;
			trips {
				mid_alert: alert {
					temperature = <90000>;
					hysteresis = <5000>;
					type = "passive";
				};
				mid_crit: crit {
					temperature = <115000>;
					hysteresis = <0>;
					type = "critical";
				};
			};
			cooling-maps {
				map0 {
					trip = <&mid_alert>;
					cooling-device = <&cpu4 THERMAL_NO_LIMIT THERMAL_NO_LIMIT>;
				};
			};
		};

		little-thermal {
			polling-delay-passive = <250>;
			polling-delay = <1000>;
			thermal-sensors = <&acpm_tmu 2>;
			sustainable-power = <800>;
			trips {
				little_alert: alert {
					temperature = <90000>;
					hysteresis = <5000>;
					type = "passive";
				};
				little_crit: crit {
					temperature = <115000>;
					hysteresis = <0>;
					type = "critical";
				};
			};
			cooling-maps {
				map0 {
					trip = <&little_alert>;
					cooling-device = <&cpu0 THERMAL_NO_LIMIT THERMAL_NO_LIMIT>;
				};
			};
		};

		g3d-thermal {
			polling-delay-passive = <250>;
			polling-delay = <1000>;
			thermal-sensors = <&acpm_tmu 3>;
			trips {
				g3d_alert: alert {
					temperature = <90000>;
					hysteresis = <5000>;
					type = "passive";
				};
				g3d_crit: crit {
					temperature = <115000>;
					hysteresis = <0>;
					type = "critical";
				};
			};
			cooling-maps {
				map0 {
					trip = <&g3d_alert>;
					cooling-device = <&gpu THERMAL_NO_LIMIT THERMAL_NO_LIMIT>;
				};
			};
		};

		/*
		 * On-die ISP (4) and TPU (5) TMU sensors. The ACPM TMU exposes
		 * 6 sensors (BIG/MID/LIT/GPU/ISP/TPU); these two are diagnostic-
		 * only - a headless felix drives neither block, but their power
		 * domains sit ungated (no genpd on mainline), so these zones
		 * instrument that idle-heat contribution and any future power-
		 * domain gating. No cooling-map: no DVFS knob throttles them.
		 * Critical trip kept as a graceful-shutdown backstop.
		 */
		isp-thermal {
			polling-delay-passive = <0>;
			polling-delay = <1000>;
			thermal-sensors = <&acpm_tmu 4>;
			trips {
				isp_crit: crit {
					temperature = <115000>;
					hysteresis = <0>;
					type = "critical";
				};
			};
		};

		tpu-thermal {
			polling-delay-passive = <0>;
			polling-delay = <1000>;
			thermal-sensors = <&acpm_tmu 5>;
			trips {
				tpu_crit: crit {
					temperature = <115000>;
					hysteresis = <0>;
					type = "critical";
				};
			};
		};
	};

	/* ------------------------------------------------------------------ */
	/* Pin controllers                                                      */
	/* ------------------------------------------------------------------ */

	/* 0: GPIO_ALIVE */
	pinctrl_0: pinctrl@180d0000 {
		compatible = "google,gs201-pinctrl";
		reg = <0x0 0x180d0000 0x1000>;
		wakeup-interrupt-controller {
			compatible = "google,gs101-wakeup-eint",
				     "samsung,exynos850-wakeup-eint",
				     "samsung,exynos7-wakeup-eint";
		};
		/*
		 * ALIVE EINTW banks. The samsung pinctrl driver needs a DT child
		 * node per bank (names match gs201_pin_alive in
		 * pinctrl-exynos-arm64.c) for the of_node/phandle; the old flat
		 * model tripped "Missing node for bank gpaN - invalid DTB" and
		 * left no <&gpa9> for the MAX77759 TCPC IRQ. Per-pin GIC SPIs are
		 * sequential from 0; gs201 gpa2 has 4 pins (gs101 had 5) so every
		 * later bank shifts down one vs gs101.
		 */
		gpa0: gpa0-gpio-bank {
			gpio-controller;
			#gpio-cells = <2>;
			interrupt-controller;
			#interrupt-cells = <2>;
			interrupt-parent = <&gic>;
			interrupts = <GIC_SPI 0 IRQ_TYPE_LEVEL_HIGH>,
				     <GIC_SPI 1 IRQ_TYPE_LEVEL_HIGH>,
				     <GIC_SPI 2 IRQ_TYPE_LEVEL_HIGH>,
				     <GIC_SPI 3 IRQ_TYPE_LEVEL_HIGH>,
				     <GIC_SPI 4 IRQ_TYPE_LEVEL_HIGH>,
				     <GIC_SPI 5 IRQ_TYPE_LEVEL_HIGH>,
				     <GIC_SPI 6 IRQ_TYPE_LEVEL_HIGH>,
				     <GIC_SPI 7 IRQ_TYPE_LEVEL_HIGH>;
		};

		gpa1: gpa1-gpio-bank {
			gpio-controller;
			#gpio-cells = <2>;
			interrupt-controller;
			#interrupt-cells = <2>;
			interrupt-parent = <&gic>;
			interrupts = <GIC_SPI 8 IRQ_TYPE_LEVEL_HIGH>,
				     <GIC_SPI 9 IRQ_TYPE_LEVEL_HIGH>,
				     <GIC_SPI 10 IRQ_TYPE_LEVEL_HIGH>,
				     <GIC_SPI 11 IRQ_TYPE_LEVEL_HIGH>,
				     <GIC_SPI 12 IRQ_TYPE_LEVEL_HIGH>,
				     <GIC_SPI 13 IRQ_TYPE_LEVEL_HIGH>,
				     <GIC_SPI 14 IRQ_TYPE_LEVEL_HIGH>;
		};

		gpa2: gpa2-gpio-bank {
			gpio-controller;
			#gpio-cells = <2>;
			interrupt-controller;
			#interrupt-cells = <2>;
			interrupt-parent = <&gic>;
			interrupts = <GIC_SPI 15 IRQ_TYPE_LEVEL_HIGH>,
				     <GIC_SPI 16 IRQ_TYPE_LEVEL_HIGH>,
				     <GIC_SPI 17 IRQ_TYPE_LEVEL_HIGH>,
				     <GIC_SPI 18 IRQ_TYPE_LEVEL_HIGH>;
		};

		gpa3: gpa3-gpio-bank {
			gpio-controller;
			#gpio-cells = <2>;
			interrupt-controller;
			#interrupt-cells = <2>;
			interrupt-parent = <&gic>;
			interrupts = <GIC_SPI 19 IRQ_TYPE_LEVEL_HIGH>,
				     <GIC_SPI 20 IRQ_TYPE_LEVEL_HIGH>,
				     <GIC_SPI 21 IRQ_TYPE_LEVEL_HIGH>,
				     <GIC_SPI 22 IRQ_TYPE_LEVEL_HIGH>;
		};

		gpa4: gpa4-gpio-bank {
			gpio-controller;
			#gpio-cells = <2>;
			interrupt-controller;
			#interrupt-cells = <2>;
			interrupt-parent = <&gic>;
			interrupts = <GIC_SPI 23 IRQ_TYPE_LEVEL_HIGH>,
				     <GIC_SPI 24 IRQ_TYPE_LEVEL_HIGH>,
				     <GIC_SPI 25 IRQ_TYPE_LEVEL_HIGH>,
				     <GIC_SPI 26 IRQ_TYPE_LEVEL_HIGH>;
		};

		gpa5: gpa5-gpio-bank {
			gpio-controller;
			#gpio-cells = <2>;
			interrupt-controller;
			#interrupt-cells = <2>;
			interrupt-parent = <&gic>;
			interrupts = <GIC_SPI 27 IRQ_TYPE_LEVEL_HIGH>,
				     <GIC_SPI 28 IRQ_TYPE_LEVEL_HIGH>,
				     <GIC_SPI 29 IRQ_TYPE_LEVEL_HIGH>,
				     <GIC_SPI 30 IRQ_TYPE_LEVEL_HIGH>,
				     <GIC_SPI 31 IRQ_TYPE_LEVEL_HIGH>,
				     <GIC_SPI 32 IRQ_TYPE_LEVEL_HIGH>,
				     <GIC_SPI 33 IRQ_TYPE_LEVEL_HIGH>;
		};

		gpa9: gpa9-gpio-bank {
			gpio-controller;
			#gpio-cells = <2>;
			interrupt-controller;
			#interrupt-cells = <2>;
			interrupt-parent = <&gic>;
			interrupts = <GIC_SPI 34 IRQ_TYPE_LEVEL_HIGH>,
				     <GIC_SPI 35 IRQ_TYPE_LEVEL_HIGH>,
				     <GIC_SPI 36 IRQ_TYPE_LEVEL_HIGH>,
				     <GIC_SPI 37 IRQ_TYPE_LEVEL_HIGH>,
				     <GIC_SPI 38 IRQ_TYPE_LEVEL_HIGH>,
				     <GIC_SPI 39 IRQ_TYPE_LEVEL_HIGH>,
				     <GIC_SPI 40 IRQ_TYPE_LEVEL_HIGH>,
				     <GIC_SPI 41 IRQ_TYPE_LEVEL_HIGH>;
		};

		gpa10: gpa10-gpio-bank {
			gpio-controller;
			#gpio-cells = <2>;
			interrupt-controller;
			#interrupt-cells = <2>;
			interrupt-parent = <&gic>;
			interrupts = <GIC_SPI 42 IRQ_TYPE_LEVEL_HIGH>,
				     <GIC_SPI 43 IRQ_TYPE_LEVEL_HIGH>;
		};
	};

	/* 1: GPIO_FAR_ALIVE */
	pinctrl_1: pinctrl@180e0000 {
		compatible = "google,gs201-pinctrl";
		reg = <0x0 0x180e0000 0x1000>;
		wakeup-interrupt-controller {
			compatible = "google,gs101-wakeup-eint",
				     "samsung,exynos850-wakeup-eint",
				     "samsung,exynos7-wakeup-eint";
		};
		gpa6: gpa6-gpio-bank {
			gpio-controller;
			#gpio-cells = <2>;
			interrupt-controller;
			#interrupt-cells = <2>;
			interrupt-parent = <&gic>;
			interrupts = <GIC_SPI 44 IRQ_TYPE_LEVEL_HIGH>,
				     <GIC_SPI 45 IRQ_TYPE_LEVEL_HIGH>,
				     <GIC_SPI 46 IRQ_TYPE_LEVEL_HIGH>,
				     <GIC_SPI 47 IRQ_TYPE_LEVEL_HIGH>,
				     <GIC_SPI 48 IRQ_TYPE_LEVEL_HIGH>,
				     <GIC_SPI 49 IRQ_TYPE_LEVEL_HIGH>,
				     <GIC_SPI 50 IRQ_TYPE_LEVEL_HIGH>,
				     <GIC_SPI 51 IRQ_TYPE_LEVEL_HIGH>;
		};

		gpa7: gpa7-gpio-bank {
			gpio-controller;
			#gpio-cells = <2>;
			interrupt-controller;
			#interrupt-cells = <2>;
			interrupt-parent = <&gic>;
			interrupts = <GIC_SPI 52 IRQ_TYPE_LEVEL_HIGH>,
				     <GIC_SPI 53 IRQ_TYPE_LEVEL_HIGH>,
				     <GIC_SPI 54 IRQ_TYPE_LEVEL_HIGH>,
				     <GIC_SPI 55 IRQ_TYPE_LEVEL_HIGH>;
		};

		gpa8: gpa8-gpio-bank {
			gpio-controller;
			#gpio-cells = <2>;
			interrupt-controller;
			#interrupt-cells = <2>;
			interrupt-parent = <&gic>;
			interrupts = <GIC_SPI 56 IRQ_TYPE_LEVEL_HIGH>,
				     <GIC_SPI 57 IRQ_TYPE_LEVEL_HIGH>,
				     <GIC_SPI 58 IRQ_TYPE_LEVEL_HIGH>,
				     <GIC_SPI 59 IRQ_TYPE_LEVEL_HIGH>,
				     <GIC_SPI 60 IRQ_TYPE_LEVEL_HIGH>,
				     <GIC_SPI 61 IRQ_TYPE_LEVEL_HIGH>,
				     <GIC_SPI 62 IRQ_TYPE_LEVEL_HIGH>,
				     <GIC_SPI 63 IRQ_TYPE_LEVEL_HIGH>;
		};

		gpa11: gpa11-gpio-bank {
			gpio-controller;
			#gpio-cells = <2>;
			interrupt-controller;
			#interrupt-cells = <2>;
			interrupt-parent = <&gic>;
			interrupts = <GIC_SPI 64 IRQ_TYPE_LEVEL_HIGH>,
				     <GIC_SPI 65 IRQ_TYPE_LEVEL_HIGH>;
		};
	};

	/* 2: GPIO_GSACORE (no interrupts to AP) */
	pinctrl_2: pinctrl@17a80000 {
		compatible = "google,gs201-pinctrl";
		reg = <0x0 0x17a80000 0x1000>;
		gpio-controller;
		#gpio-cells = <2>;
	};

	/* 3: GPIO_GSACTRL (no interrupts to AP) */
	pinctrl_3: pinctrl@17940000 {
		compatible = "google,gs201-pinctrl";
		reg = <0x0 0x17940000 0x1000>;
		gpio-controller;
		#gpio-cells = <2>;
	};

	/* 4: GPIO_PERIC0 */
	pinctrl_4: pinctrl@10840000 {
		compatible = "google,gs201-pinctrl";
		reg = <0x0 0x10840000 0x1000>;
		interrupts = <GIC_SPI 664 IRQ_TYPE_LEVEL_HIGH>;
		gpio-controller;
		#gpio-cells = <2>;
		interrupt-controller;
		#interrupt-cells = <2>;

		/*
		 * gpp0 bank — used for the UFS device's VCC enable pin
		 * (gpp0-1, see ufs_fixed_vcc below). The Samsung pinctrl
		 * driver requires explicit bank subnodes; without this,
		 * `<&gpp0 1 0>` won't resolve and ufs_fixed_vcc fails to
		 * register, leaving the UFS chip unpowered.
		 */
		gpp0: gpp0-gpio-bank {
			gpio-controller;
			#gpio-cells = <2>;
			interrupt-controller;
			#interrupt-cells = <2>;
		};


		/*
		 * Force gpp0-1 into GPIO output function so the
		 * ufs_fixed_vcc regulator can actually drive the UFS
		 * device's VCC enable line. Mainline Samsung pinctrl
		 * doesn't automatically switch the pin's alt-function
		 * when a consumer requests it as a GPIO; without an
		 * explicit pin-function = 0 entry, the bootloader's
		 * leftover function (or POR default) stays selected and
		 * gpio_set_value writes never reach the pad.
		 */
		ufs_vcc_en: ufs-vcc-en {
			samsung,pins = "gpp0-1";
			samsung,pin-function = <0>;
			samsung,pin-pud = <0>;
		};

		/*
		 * UART0 / USI0_UART pin function. Same pins, function, and
		 * pud setting as gs101 (gs101-pinctrl.dtsi:524) — felix's
		 * uart0 lives on gpp1-2/gpp1-3 with alt-function 2. The
		 * bootloader has typically already programmed these (UART
		 * works from earlycon without pinctrl), but declaring the
		 * state here lets samsung_tty's probe call pinctrl_select
		 * cleanly and survives any GPIO consumer that might toggle
		 * the bank.
		 */
		uart0_bus: uart0-bus-pins {
			samsung,pins = "gpp1-2", "gpp1-3";
			samsung,pin-function = <2>;
			samsung,pin-pud = <0>;
		};

		/*
		 * Outer-panel (dsim1) tearing-effect line. gpp0-4 carries the
		 * ea8182 panel's TE signal; pin-function 0xf selects the EINT
		 * alt-function so gpio_to_irq() yields the TE interrupt and the
		 * decon can HW-trigger command mode from it. The dsim driver
		 * selects hw_te_on at enable / hw_te_off at disable.
		 */
		disp_te_sec_on: disp-te-sec-on {
			samsung,pins = "gpp0-4";
			samsung,pin-function = <0xf>;
		};

		disp_te_sec_off: disp-te-sec-off {
			samsung,pins = "gpp0-4";
			samsung,pin-function = <0>;
		};
	};

	/* 5: GPIO_PERIC1 */
	pinctrl_5: pinctrl@10c40000 {
		compatible = "google,gs201-pinctrl";
		reg = <0x0 0x10c40000 0x1000>;
		interrupts = <GIC_SPI 683 IRQ_TYPE_LEVEL_HIGH>;
		gpio-controller;
		#gpio-cells = <2>;
		interrupt-controller;
		#interrupt-cells = <2>;

		/*
		 * gpp23 bank — the outer panel's reset line is gpp23-0
		 * (see gs201-felix.dts panel@0 reset-gpios). Like the gpp0
		 * UFS-VCC case above, the Samsung pinctrl driver needs an
		 * explicit bank subnode for `<&gpp23 0 ...>` to resolve;
		 * without it the panel's devm_gpiod_get("reset") fails and
		 * the ea8182 driver aborts probe.
		 */
		gpp23: gpp23-gpio-bank {
			gpio-controller;
			#gpio-cells = <2>;
			interrupt-controller;
			#interrupt-cells = <2>;
		};
	};

	/* 6: GPIO_HSI1 */
	pinctrl_6: pinctrl@11840000 {
		compatible = "google,gs201-pinctrl";
		reg = <0x0 0x11840000 0x1000>;
		interrupts = <GIC_SPI 387 IRQ_TYPE_LEVEL_HIGH>;
		gpio-controller;
		#gpio-cells = <2>;
		interrupt-controller;
		#interrupt-cells = <2>;
	};

	/* 7: GPIO_HSI2 */
	pinctrl_7: pinctrl@14440000 {
		compatible = "google,gs201-pinctrl";
		reg = <0x0 0x14440000 0x1000>;
		interrupts = <GIC_SPI 421 IRQ_TYPE_LEVEL_HIGH>;
		gpio-controller;
		#gpio-cells = <2>;
		interrupt-controller;
		#interrupt-cells = <2>;
	};

	/* 8: GPIO_HSI2UFS — split from HSI2 vs GS101 */
	pinctrl_8: pinctrl@14460000 {
		compatible = "google,gs201-pinctrl";
		reg = <0x0 0x14460000 0x1000>;
		interrupts = <GIC_SPI 422 IRQ_TYPE_LEVEL_HIGH>;
		gpio-controller;
		#gpio-cells = <2>;
		interrupt-controller;
		#interrupt-cells = <2>;

		/*
		 * gph3 bank (2 pins at offset 0x000) — the only bank under
		 * pinctrl_8. The gs201 pin-controller driver has the layout
		 * hardcoded (gs201_pin_hsi2ufs[] in pinctrl-exynos-arm64.c),
		 * but it still needs this subnode to exist so pin references
		 * like "gph3-0" in the pin-state nodes below can be resolved.
		 */
		gph3: gph3-gpio-bank {
			gpio-controller;
			#gpio-cells = <2>;
			interrupt-controller;
			#interrupt-cells = <2>;
		};

		/*
		 * UFS GPIO pin-mux states, consumed by ufs_0's pinctrl-0.
		 * These belong nested in their owning pin-controller — placing
		 * them at the root of the tree (as this file originally did)
		 * makes fw_devlink treat the phandle targets as supplier
		 * *devices* and defer ufs_0's probe forever waiting for a
		 * driver that will never bind to a pinctrl-state subnode.
		 */
		/*
		 * Both pins use pin-function = 2 (UFS host-controller alt
		 * function), not GPIO. With GPIO, the host controller's
		 * internal HCI_GPIO_OUT reset toggle (driven by
		 * exynos_ufs_dev_hw_reset()) never reaches the UFS device's
		 * RST_N pin, so the device can't respond to LINKSTARTUP and
		 * link startup fails 4× then aborts. Values match AOSP
		 * gs201-pinctrl.dtsi.
		 */
		ufs_rst_n: ufs-rst-n {
			samsung,pins = "gph3-1";
			samsung,pin-function = <2>;
			samsung,pin-pud = <0>;
			samsung,pin-con-pdn = <3>;
			samsung,pin-pud-pdn = <0>;
		};

		ufs_refclk_out: ufs-refclk-out {
			samsung,pins = "gph3-0";
			samsung,pin-function = <2>;
			samsung,pin-pud = <0>;
			samsung,pin-con-pdn = <3>;
			samsung,pin-pud-pdn = <0>;
		};
	};

	/* ------------------------------------------------------------------ */
	/* Serial console (UART0 / USI0_UART, PERIC0)                         */
	/* ------------------------------------------------------------------ */

	serial_0: serial@10a00000 {
		/*
		 * google,gs101-uart (NOT samsung,exynos850-uart) so the
		 * driver picks up gs101_serial_drv_data with iotype =
		 * UPIO_MEM32. gs201's UART register block requires
		 * 32-bit-aligned access — a byte write to UTXH (which
		 * is what samsung_tty's wr_reg() does under UPIO_MEM)
		 * raises an asynchronous SError that the kernel ultimately
		 * panics on inside console_unlock(). Earlycon already
		 * uses 32-bit access (cmdline: earlycon=exynos4210,
		 * mmio32,...), so it works regardless. Empirically
		 * verified on felix 2026-05-03.
		 */
		compatible = "google,gs101-uart";
		reg = <0x0 0x10a00000 0x100>;
		samsung,fifo-size = <256>;
		interrupts = <GIC_SPI 673 IRQ_TYPE_LEVEL_HIGH>;
		/*
		 * gs201 has no PERIC0_TOP1 cluster (gs101's TOP1 IPCLK_0 /
		 * PCLK_0 gates don't exist on gs201 hardware). Wire directly
		 * to the per-peripheral USI0_UART gate (CLK_GOUT_PERIC0_CLK_
		 * PERIC0_USI0_UART_CLK) and the cmu_peric0 USI0_UART divider
		 * (CLK_DOUT_PERIC0_USI0_UART) — both register at gs201's
		 * shifted offsets in peric0_cmu_info_gs201 (clk-gs101.c).
		 */
		clocks = <&cmu_peric0 CLK_GOUT_PERIC0_CLK_PERIC0_USI0_UART_CLK>,
			 <&cmu_peric0 CLK_DOUT_PERIC0_USI0_UART>;
		clock-names = "uart", "clk_uart_baud0";
		pinctrl-0 = <&uart0_bus>;
		pinctrl-names = "default";
		status = "disabled";
	};

	/* ------------------------------------------------------------------ */
	/* UFS storage (HSI2 subsystem)                                        */
	/* ------------------------------------------------------------------ */

	sysreg_hsi2: syscon@14420000 {
		compatible = "google,gs201-hsi2-sysreg", "syscon";
		reg = <0x0 0x14420000 0x1000>;
	};

	/*
	 * UFS device VCC enable. The KIOXIA THGJFGT1E45BAIPB's main power
	 * rail is gated by gpp0-1 on felix; the bootloader drives it high to
	 * talk to the device, then drops it during shutdown ("[I] [UFS]
	 * shutdown complete"). Without this regulator, the kernel's UFS
	 * driver sees a powered-down device — link startup completes (host
	 * PHY has independent power) but every NOP OUT response slot stays
	 * at 0 because the device chip isn't running. Matches AOSP's
	 * gs201-ufs.dtsi ufs_fixed_vcc.
	 */
	ufs_fixed_vcc: regulator-ufs-vcc {
		compatible = "regulator-fixed";
		regulator-name = "ufs-vcc";
		gpio = <&gpp0 1 GPIO_ACTIVE_HIGH>;
		enable-active-high;
		/*
		 * Deliberately omit regulator-boot-on. The bootloader's
		 * `[I] [UFS] shutdown complete` drops VCC before handing
		 * off, so when the kernel boots the rail is OFF. With
		 * regulator-boot-on, the framework would think it's
		 * already on and skip the GPIO drive when UFS calls
		 * regulator_enable. Without it, the framework runs the
		 * fixed-voltage enable path and gpiod_set_value actually
		 * drives gpp0-1 high.
		 *
		 * Power-on settling time. UFS device VCC needs to be
		 * stable before the host issues commands; without this
		 * the link comes up but NOP OUT can race the device's
		 * internal init.
		 */
		startup-delay-us = <2000>;
		pinctrl-names = "default";
		pinctrl-0 = <&ufs_vcc_en>;
	};

	ufs_0: ufs@14700000 {
		compatible = "google,gs201-ufs";
		reg = <0x0 0x14700000 0x200>,   /* HCI standard  */
		      <0x0 0x14701100 0x200>,   /* vendor HCI    */
		      <0x0 0x14780000 0xa000>,  /* UNIPRO        */
		      <0x0 0x14600000 0x100>;   /* UFS protector */
		reg-names = "hci", "vs_hci", "unipro", "ufsp";
		interrupts = <GIC_SPI 453 IRQ_TYPE_LEVEL_HIGH>;
		pinctrl-names = "default";
		pinctrl-0 = <&ufs_rst_n &ufs_refclk_out>;
		clocks = <&ufs_aclk>, <&ufs_unipro>, <&ufs_aclk>,
			 <&ufs_aclk>, <&ufs_aclk>,   <&ufs_aclk>;
		clock-names = "core_clk", "sclk_unipro_main", "fmp",
			      "aclk", "pclk", "sysreg";
		freq-table-hz = <0 0>, <0 0>, <0 0>, <0 0>, <0 0>, <0 0>;
		phys = <&ufs_0_phy>;
		phy-names = "ufs-phy";
		vcc-supply = <&ufs_fixed_vcc>;
		ufs,pmd-attr-lane = /bits/ 8 <2>;
		ufs,pmd-attr-gear = /bits/ 8 <4>;
		/*
		 * `dma-coherent` is required on gs201. exynos_ufs_parse_dt sets
		 * `iocc_val = iocc_mask` only when of_dma_is_coherent() is true;
		 * otherwise it sets iocc_val = 0, which causes
		 * exynos_ufs_shareability's regmap_update_bits(sysreg+0x710,
		 * mask=0x3, val=0) to actively CLEAR the bootloader's IOCC RD/WR
		 * Sharable bits (observed: bootloader 0x13 → kernel 0x10). With
		 * the bits cleared, the controller's AXI transactions are issued
		 * with Device-memory semantics, so its UPIU writes never reach
		 * CPU-visible DRAM (proven via magic-stamp test — controller fires
		 * UTRCS but the response slot stays at 0xAB through the entire
		 * transaction). Match AOSP's gs201-ufs.dtsi which has both
		 * `dma-coherent` and `ufs-iocc { val = <0x3>; }`.
		 */
		dma-coherent;
		samsung,sysreg = <&sysreg_hsi2 0x710>;
	};

	/* UFS PHY ref_clk is the 24.576 MHz SoC oscillator (gs101 uses the
	 * same here). The PHY init sequence in phy-gs101-ufs.c writes ~70
	 * magic register values calibrated for this reference frequency. */
	ufs_0_phy: phy@14704000 {
		compatible = "google,gs201-ufs-phy";
		reg = <0x0 0x14704000 0x3000>;
		reg-names = "phy-pma";
		clocks = <&oscclk>;
		clock-names = "ref_clk";
		samsung,pmu-syscon = <&pmu_alive>;
		#phy-cells = <0>;
	};

	/* UFS pin-mux states (ufs_rst_n, ufs_refclk_out) live inside pinctrl_8
	 * above — see the comment there for why they must not be at root. */

	/* ------------------------------------------------------------------ */
	/* PMU syscon (needed by UFS PHY and power domain drivers)             */
	/* ------------------------------------------------------------------ */

	/*
	 * Drop the "syscon" fallback compat: when both are present, the
	 * generic of_syscon driver registers a direct-MMIO regmap for the
	 * node and races/shadows the SMC-routed regmap that exynos-pmu.c
	 * installs via of_syscon_register_regmap(). With only
	 * "google,gs201-pmu" present (matching gs101.dtsi), exynos-pmu wins
	 * and syscon_regmap_lookup_by_phandle() returns the SMC regmap, so
	 * UFS PHY isolation writes to PMU_ALIVE+0x3ec8 go through BL31
	 * instead of aborting.
	 */
	pmu_alive: pmu@18060000 {
		compatible = "google,gs201-pmu";
		reg = <0x0 0x18060000 0x10000>;
	};

	/* ------------------------------------------------------------------ */
	/* USB 3.1 (HSI0 subsystem) — type-C port on the Pixel Fold           */
	/*                                                                    */
	/* Layout mirrors gs101.dtsi (Pixel 6) at 0x1100_0000 — gs201 reuses  */
	/* the same HSI0 register map per AOSP cal-if. Driver bindings:       */
	/*   - cmu_hsi0:    google,gs201-cmu-hsi0  (clk-gs101.c, gs201 entry  */
	/*                  shares hsi0_cmu_info).                            */
	/*   - sysreg_hsi0: google,gs101-hsi0-sysreg + syscon (no gs201       */
	/*                  variant; register layout is identical).           */
	/*   - usbdrd31_phy: google,gs101-usb31drd-phy (phy-exynos5-usbdrd).  */
	/*   - usbdrd31:     google,gs101-dwusb3 (dwc3-exynos.c).             */
	/*                                                                    */
	/* HSI0 user-mux input parents (bus / dpgtc / usb31drd / usbdpdbg):   */
	/* gs101 sources these from cmu_top dout outputs; gs201 leaves        */
	/* cmu_top disabled (clk_divider_recalc_rate panics on its rate       */
	/* table — see top-of-file note), so we feed cmu_hsi0 from fixed-rate */
	/* stubs at the AOSP-typical rates instead. Same workaround pattern   */
	/* as cmu_peric0 above. Rates may need refinement once cmu_top boots; */
	/* until then the user-muxes will land on whatever bootloader-       */
	/* programmed value matches one of these stubs.                       */
	/*                                                                    */
	/* Status = "disabled" on every node here. felix.dts (or a future    */
	/* board file) re-enables them when the board has the necessary      */
	/* regulators / TCPC / role-switch wiring up.                         */
	/* ------------------------------------------------------------------ */

	hsi0_bus_clk: hsi0-bus-clk {
		compatible = "fixed-clock";
		#clock-cells = <0>;
		clock-frequency = <400000000>;
		clock-output-names = "hsi0_bus";
	};

	hsi0_dpgtc_clk: hsi0-dpgtc-clk {
		compatible = "fixed-clock";
		#clock-cells = <0>;
		clock-frequency = <200000000>;
		clock-output-names = "hsi0_dpgtc";
	};

	hsi0_usb31drd_clk: hsi0-usb31drd-clk {
		compatible = "fixed-clock";
		#clock-cells = <0>;
		clock-frequency = <19200000>;
		clock-output-names = "hsi0_usb31drd";
	};

	hsi0_usbdpdbg_clk: hsi0-usbdpdbg-clk {
		compatible = "fixed-clock";
		#clock-cells = <0>;
		clock-frequency = <24576000>;
		clock-output-names = "hsi0_usbdpdbg";
	};

	/*
	 * USB PHY reference-clock rate stub. The mainline PHY driver checks
	 * `clk_get_rate("ref")` against a fixed allow-list (9.6/10/12/19.2/20/
	 * 24/26/50 MHz, strict equality). When fed via cmu_hsi0 the rate
	 * walks back through the user-mux/PLL chain — which on gs201 reads
	 * back the bootloader-programmed PLL (~614.4 MHz) because cmu_top
	 * stays disabled, and PHY probe rejects the rate with -EINVAL.
	 *
	 * Workaround: tell the driver "ref is 26 MHz" via a fixed-clock,
	 * matching the AOSP/cal-if rate that the gs101 clock name suffix
	 * `_REFCLK_26` already reflects. The actual REFCLK pin going into
	 * the PHY is driven by the bootloader-programmed cmu_hsi0 hardware,
	 * not this stub — the stub only feeds the kernel's rate accounting.
	 */
	hsi0_ref_clk: hsi0-ref-clk {
		compatible = "fixed-clock";
		#clock-cells = <0>;
		clock-frequency = <26000000>;
		clock-output-names = "hsi0_ref";
	};

	cmu_hsi0: clock-controller@11000000 {
		compatible = "google,gs201-cmu-hsi0";
		reg = <0x0 0x11000000 0x10000>;
		#clock-cells = <1>;
		clocks = <&oscclk>,
			 <&hsi0_bus_clk>,
			 <&hsi0_dpgtc_clk>,
			 <&hsi0_usb31drd_clk>,
			 <&hsi0_usbdpdbg_clk>;
		clock-names = "oscclk", "bus", "dpgtc", "usb31drd", "usbdpdbg";
		samsung,sysreg = <&sysreg_hsi0>;
	};

	sysreg_hsi0: syscon@11020000 {
		compatible = "google,gs101-hsi0-sysreg", "syscon";
		reg = <0x0 0x11020000 0x10000>;
		clocks = <&cmu_hsi0 CLK_GOUT_HSI0_SYSREG_HSI0_PCLK>;
	};

	/*
	 * gs201 PHY register layout differs from gs101 mainline expects:
	 *   - "phy" (UTMI registers, LINKCTRL at +0x04, UTMI at +0x50, etc.):
	 *     gs201 = 0x11200000 (AOSP), gs101 mainline driver expects same
	 *     symbol at its own base — driver hits SError in
	 *     exynos850_usbdrd_utmi_init's first readl(LINKCTRL) when the DT
	 *     points to gs101's 0x11100000 (which is gs201's PMA region).
	 *   - "pcs" stays at 0x110f0000 on both gs101 and gs201 (size differs:
	 *     mainline=0x800, AOSP=0x2800; mainline driver only writes within
	 *     0x800 so size shouldn't matter).
	 *   - "pma" gs201 = 0x11100000 / size 0x800 (AOSP), mainline gs101
	 *     driver expects 0x110e0000 / size 0x2800. Different address AND
	 *     size — pipe3 (SuperSpeed) init will likely abort, but Phase A
	 *     is HS-only (maximum-speed = "high-speed" in felix.dts) so we may
	 *     not hit pipe3 init anyway. If it does fire we'll see in the
	 *     trace and remap pma to 0x11100000 too.
	 */
	/*
	 * gs201 Stage-2 MPU instance for the HSI0 master (the dwc3
	 * USB31DRD wrapper). AOSP DT puts s2mpus = <&s2mpu_hsi0>; on
	 * the USB PHY node so the AOSP s2mpu driver can program
	 * per-client allow tables when HSI0 transitions through power
	 * states. Mainline has no S2MPU driver; we register the device
	 * under a probe-only stub (drivers/soc/samsung/gs201-s2mpu-stub.c,
	 * CONFIG_GS201_S2MPU_STUB=y in felix.config) so the OF node
	 * binds without generating "deferred probe pending" spam, and we
	 * can confirm at boot that ATF/firmware doesn't gate HSI0 master
	 * permissions on a kernel-side claim.
	 *
	 * IRQ 373 = AOSP IRQ_SYSMMU_USB_S2_HSI0
	 * (private/google-modules/soc/gs/include/dt-bindings/
	 * interrupt-controller/gs201.h:387). Reg layout matches AOSP
	 * gs201-s2mpu.dtsi:140.
	 */
	s2mpu_hsi0: s2mpu@11070000 {
		compatible = "google,s2mpu";
		reg = <0x0 0x11070000 0x10000>;
		interrupts = <GIC_SPI 373 IRQ_TYPE_LEVEL_HIGH>;
		status = "disabled";
	};

	usbdrd31_phy: phy@11200000 {
		compatible = "google,gs201-usb31drd-phy";
		/*
		 * pcs @0x11100000 (0x800), pma @0x110f0000 (0x2800). These were
		 * swapped previously: the gen2 PMA CMN/TRSV block (needs the 0x2800
		 * map, regs to ~0x1f0c) lives at 0x110f0000 per AOSP (reg_phy2), and
		 * 0x11100000 is the smaller PCS. The swap sent all PMA config writes
		 * to the wrong region, so the SS LCPLL never locked.
		 */
		reg = <0x0 0x11200000 0x0200>,
		      <0x0 0x11100000 0x0800>,
		      <0x0 0x110f0000 0x2800>;
		reg-names = "phy", "pcs", "pma";
		clocks = <&cmu_hsi0 CLK_GOUT_HSI0_USB31DRD_ACLK_PHYCTRL>,
			 <&cmu_hsi0 CLK_GOUT_HSI0_USB31DRD_I_USB31DRD_REF_CLK_40>,
			 <&cmu_hsi0 CLK_GOUT_HSI0_UASC_HSI0_CTRL_ACLK>,
			 <&cmu_hsi0 CLK_GOUT_HSI0_UASC_HSI0_CTRL_PCLK>,
			 <&cmu_hsi0 CLK_GOUT_HSI0_USB31DRD_I_USBDPPHY_SCL_APB_PCLK>;
		clock-names = "phy", "ref", "ctrl_aclk", "ctrl_pclk", "scl_pclk";
		#phy-cells = <1>;
		samsung,pmu-syscon = <&pmu_alive>;
		status = "disabled";
	};

	/*
	 * gs201 shifts the DWC3 controller wrapper +0x100000 from gs101
	 * (0x11210000 vs gs101's 0x11110000). AOSP gs201.dtsi places `udc` at
	 * 0x11210000 with `IRQ_USB31DRD_GIC_0_HSI0 = 379`. Reading mainline-
	 * style gs101 register names at 0x11110000 hits dead/firewalled space
	 * → synchronous external abort 0x96000010 inside dwc3_core_probe's
	 * first MMIO read. AOSP's PHY also uses 4 reg ranges including a
	 * "link" region overlapping the controller wrapper at 0x11210000;
	 * mainline phy-exynos5-usbdrd's gs101 binding only has 3, so we keep
	 * the mainline 3-range PHY layout above for now and accept that the
	 * PHY's "link" view is owned by the controller node here. If PHY
	 * power-up needs the link region, the PHY driver will need either a
	 * gs201-specific drvdata with 4 reg ranges or a shared-mapping
	 * workaround.
	 */
	usbdrd31: usb@11210000 {
		compatible = "google,gs101-dwusb3";
		ranges = <0x0 0x0 0x11210000 0x10000>;
		clocks = <&cmu_hsi0 CLK_GOUT_HSI0_USB31DRD_BUS_CLK_EARLY>,
			 <&cmu_hsi0 CLK_GOUT_HSI0_USB31DRD_I_USB31DRD_SUSPEND_CLK_26>,
			 <&cmu_hsi0 CLK_GOUT_HSI0_UASC_HSI0_LINK_ACLK>,
			 <&cmu_hsi0 CLK_GOUT_HSI0_UASC_HSI0_LINK_PCLK>;
		clock-names = "bus_early", "susp_clk", "link_aclk", "link_pclk";
		#address-cells = <1>;
		#size-cells = <1>;
		status = "disabled";

		usbdrd31_dwc3: usb@0 {
			compatible = "snps,dwc3";
			reg = <0x0 0x10000>;
			clocks = <&cmu_hsi0 CLK_GOUT_HSI0_USB31DRD_I_USB31DRD_REF_CLK_40>;
			clock-names = "ref";
			/*
			 * IRQ 379 = AOSP gs201.h IRQ_USB31DRD_GIC_0_HSI0
			 * (gs101 uses 463 for the same signal — gs201
			 * remapped). Verified against
			 * private/google-modules/soc/gs/include/dt-bindings/
			 * interrupt-controller/gs201.h:393 in source.aosp-backup.
			 */
			interrupts = <GIC_SPI 379 IRQ_TYPE_LEVEL_HIGH>;
			phys = <&usbdrd31_phy 0>, <&usbdrd31_phy 1>;
			phy-names = "usb2-phy", "usb3-phy";
			snps,has-lpm-erratum;
			snps,dis_u2_susphy_quirk;
			snps,dis_u3_susphy_quirk;
			/*
			 * gs201's USB2 PHY clock isn't free-running. The
			 * mainline dwc3 quirk clears GUSB2PHYCFG.U2_FREECLK_EXISTS
			 * AND (with our SOFITPSYNC patch in dwc3 core) sets
			 * GCTL.SOFITPSYNC=1 so SOF/ITP timing is referenced off
			 * ref_clk instead of the absent U2 freeclock. Without
			 * this, host EP0 GET_DESCRIPTOR returns EPROTO.
			 */
			snps,dis-u2-freeclk-exists-quirk;
			status = "disabled";
		};
	};

	/* ------------------------------------------------------------------ */
	/* Mali-G710 GPU — Panthor driver (CSF architecture)                   */
	/*                                                                     */
	/* The G710 is a Valhall-CSF GPU.  Clocks are ACPM DVFS-managed and   */
	/* do not require the CMU driver.                                      */
	/*                                                                     */
	/* Firmware: place arm/mali/arch10.8/mali_csffw.bin in /lib/firmware  */
	/* (extract from Android /vendor/firmware/mali_csffw.bin).            */
	/*                                                                     */
	/* TODO: add power-domains once a GS201 pmdomain driver exists.       */
	/* ------------------------------------------------------------------ */

	gpu: gpu@28000000 {
		compatible = "google,gs201-mali", "arm,mali-valhall-csf";
		reg = <0x0 0x28000000 0x480000>;

		interrupts = <GIC_SPI 328 IRQ_TYPE_LEVEL_HIGH>,
			     <GIC_SPI 329 IRQ_TYPE_LEVEL_HIGH>,
			     <GIC_SPI 330 IRQ_TYPE_LEVEL_HIGH>;
		interrupt-names = "gpu", "job", "mmu";

		/*
		 * G3D  = shader-core clock  → "core"
		 * G3DL2 = L2-cache bus clock → "stacks"
		 * Both are sourced from the ACPM DVFS provider.
		 */
		clocks = <&acpm_ipc GS201_CLK_ACPM_DVFS_G3D>,
			 <&acpm_ipc GS201_CLK_ACPM_DVFS_G3DL2>;
		clock-names = "core", "stacks";

		operating-points-v2 = <&gpu_opp>;
		dynamic-power-coefficient = <625>;
		#cooling-cells = <2>;

		/*
		 * Memory-bandwidth path GPU -> INT -> DRAM(MIF). The OPP core
		 * (dev_pm_opp_of_add_table -> _of_find_icc_paths) picks this up
		 * and, on each panthor DVFS transition, votes the active OPP's
		 * opp-peak-kBps via icc_set_bw. exynos-generic-icc turns that
		 * into MIN_FREQUENCY dev_pm_qos floors on BOTH bus_int and
		 * bus_mif (a two-node path is required: the interconnect core's
		 * apply_constraints() only calls the provider .set() for the
		 * second node of a hop, so a single-node self-path is a no-op).
		 * This is the mainline-idiomatic replacement for AOSP's mali
		 * gpu_dvfs_qos int_min + mif_min PM_QoS votes.
		 */
		interconnects = <&bus_int &bus_mif>;
	};

	/*
	 * When the gpu node gets a mali-supply regulator wired up, the OPP core
	 * rejects any opp node that omits opp-microvolt (opp_parse_microvolt:
	 * "missing although OPP managing regulators"). Every entry lists
	 * <900000> — matches the fixed-regulator stub in gs201-felix.dts. Real
	 * per-OPP voltages can replace these once an ACPM-backed regulator
	 * driver exists and can actually program the G3D rail.
	 */
	gpu_opp: opp-table-gpu {
		compatible = "operating-points-v2";
		/*
		 * G3D (shader core) frequencies in Hz. opp-peak-kBps is the DRAM
		 * bandwidth voted through the interconnect at that OPP; with
		 * bus_mif's data-clock-ratio=8 it maps to a MIF MIN_FREQUENCY of
		 * peak_kBps/8 kHz (snapped up to a MIF OPP by devfreq). The ladder
		 * keeps light GPU load near the MIF floor and pulls MIF to its
		 * 3172MHz max only at the top shader clocks (measured ~1.4-1.5x on
		 * llama.cpp/PanVK from MIF 421->3172). Tunable knob.
		 *   MIF target:  421  546 1014 1014 1352 1352 1539 1539 2028 2028 2730 3172 3172
		 */
		opp-202000000 { opp-hz = /bits/ 64 <202000000>; opp-microvolt = <900000>; opp-peak-kBps = <3368000>; };
		opp-251000000 { opp-hz = /bits/ 64 <251000000>; opp-microvolt = <900000>; opp-peak-kBps = <4368000>; };
		opp-302000000 { opp-hz = /bits/ 64 <302000000>; opp-microvolt = <900000>; opp-peak-kBps = <8112000>; };
		opp-351000000 { opp-hz = /bits/ 64 <351000000>; opp-microvolt = <900000>; opp-peak-kBps = <8112000>; };
		opp-400000000 { opp-hz = /bits/ 64 <400000000>; opp-microvolt = <900000>; opp-peak-kBps = <10816000>; };
		opp-434000000 { opp-hz = /bits/ 64 <434000000>; opp-microvolt = <900000>; opp-peak-kBps = <10816000>; };
		opp-471000000 { opp-hz = /bits/ 64 <471000000>; opp-microvolt = <900000>; opp-peak-kBps = <12312000>; };
		opp-510000000 { opp-hz = /bits/ 64 <510000000>; opp-microvolt = <900000>; opp-peak-kBps = <12312000>; };
		opp-572000000 { opp-hz = /bits/ 64 <572000000>; opp-microvolt = <900000>; opp-peak-kBps = <16224000>; };
		opp-633000000 { opp-hz = /bits/ 64 <633000000>; opp-microvolt = <900000>; opp-peak-kBps = <16224000>; };
		opp-701000000 { opp-hz = /bits/ 64 <701000000>; opp-microvolt = <900000>; opp-peak-kBps = <21840000>; };
		opp-762000000 { opp-hz = /bits/ 64 <762000000>; opp-microvolt = <900000>; opp-peak-kBps = <25376000>; };
		opp-848000000 { opp-hz = /bits/ 64 <848000000>; opp-microvolt = <900000>; opp-peak-kBps = <25376000>; };
	};

	/* ------------------------------------------------------------------ */
	/* MIF (memory interface) devfreq                                       */
	/*                                                                      */
	/* Scale the DRAM/bus frequency with real memory load instead of       */
	/* leaving it pinned at the boot rate (2028 MHz), which is a large      */
	/* constant idle-power draw. The ACPM MIF clock does freq+voltage DVFS; */
	/* PPC counters on the CCI memory ports feed the simple_ondemand        */
	/* governor.                                                            */
	/* ------------------------------------------------------------------ */

	/*
	 * exynos-bus requires a "vdd" regulator, but gs201 MIF voltage is
	 * coupled to frequency inside ACPM (no Linux-controlled rail). A fixed
	 * dummy satisfies the driver's regulator API; every OPP pins the same
	 * nominal microvolt so the dummy is never actually moved. The real
	 * per-level voltage is applied by ACPM on the frequency request.
	 */
	mif_dummy_vdd: regulator-mif-dummy {
		compatible = "regulator-fixed";
		regulator-name = "mif-dummy-vdd";
		regulator-min-microvolt = <800000>;
		regulator-max-microvolt = <800000>;
		regulator-always-on;
	};

	mif_opp: opp-table-mif {
		compatible = "operating-points-v2";
		/* Valid ACPM MIF DVFS levels (from the felix mif_int_map). */
		opp-421000000  { opp-hz = /bits/ 64 <421000000>;  opp-microvolt = <800000>; };
		opp-546000000  { opp-hz = /bits/ 64 <546000000>;  opp-microvolt = <800000>; };
		opp-1014000000 { opp-hz = /bits/ 64 <1014000000>; opp-microvolt = <800000>; };
		opp-1352000000 { opp-hz = /bits/ 64 <1352000000>; opp-microvolt = <800000>; };
		opp-1539000000 { opp-hz = /bits/ 64 <1539000000>; opp-microvolt = <800000>; };
		opp-2028000000 { opp-hz = /bits/ 64 <2028000000>; opp-microvolt = <800000>; };
		opp-2730000000 { opp-hz = /bits/ 64 <2730000000>; opp-microvolt = <800000>; };
		opp-3172000000 { opp-hz = /bits/ 64 <3172000000>; opp-microvolt = <800000>; };
	};

	/* PPC bandwidth counters on the four CCI memory-master ports. */
	ppc_mif0: ppc@1e130000 {
		compatible = "google,gs201-ppc";
		reg = <0x0 0x1e130000 0x1000>;
		event-name = "ppc-mif-cci0";
	};
	ppc_mif1: ppc@1e140000 {
		compatible = "google,gs201-ppc";
		reg = <0x0 0x1e140000 0x1000>;
		event-name = "ppc-mif-cci1";
	};
	ppc_mif2: ppc@1e150000 {
		compatible = "google,gs201-ppc";
		reg = <0x0 0x1e150000 0x1000>;
		event-name = "ppc-mif-cci2";
	};
	ppc_mif3: ppc@1e160000 {
		compatible = "google,gs201-ppc";
		reg = <0x0 0x1e160000 0x1000>;
		event-name = "ppc-mif-cci3";
	};

	bus_mif: bus-mif {
		compatible = "samsung,exynos-bus";
		clocks = <&acpm_ipc GS201_CLK_ACPM_DVFS_MIF>;
		clock-names = "bus";
		operating-points-v2 = <&mif_opp>;
		vdd-supply = <&mif_dummy_vdd>;
		devfreq-events = <&ppc_mif0 &ppc_mif1 &ppc_mif2 &ppc_mif3>;
		/*
		 * PPC transactions run ~6-7% of MIF cycles under a heavy memory
		 * load (measured on-device). exynos-bus computes utilisation as
		 * load*100/ratio over CCNT, ramping to max above load/CCNT >
		 * ratio*0.004; ratio=8 sets that threshold at ~3.2% so real
		 * memory load scales MIF up while idle (~0.4%) stays at minimum.
		 */
		exynos,saturation-ratio = <8>;

		/*
		 * Act as the DRAM/DMC interconnect provider so DMA masters can
		 * vote memory bandwidth. The gs201-ppc counters above only see
		 * CCI (CPU/coherent) traffic; the G710 GPU reaches DRAM on a path
		 * they do NOT count, so without this a pure-GPU workload leaves
		 * MIF at its 421MHz floor. exynos-generic-icc converts a
		 * bandwidth vote to freq = peak_kBps / data-clock-ratio and drops
		 * it in as a MIN_FREQUENCY dev_pm_qos request (a floor that
		 * composes with simple_ondemand). ratio 8 => 3172MHz needs
		 * 25.376 GB/s, matching the GPU OPP table's top opp-peak-kBps.
		 */
		#interconnect-cells = <0>;
		samsung,data-clock-ratio = <8>;
	};

	/*
	 * INT (internal NoC) devfreq. Sits between DMA masters (GPU, display)
	 * and MIF on the path to DRAM. Modelled as a passive exynos-bus that
	 * follows bus_mif, and as the source interconnect node for the GPU's
	 * bandwidth path (GPU -> bus_int -> bus_mif). The ACPM INT clock does
	 * freq+voltage DVFS (voltage coupled in firmware, same dummy-vdd story
	 * as MIF). Frequencies are the AOSP gs201 INT DVFS span (100-533MHz);
	 * ACPM snaps each request to its nearest ECT level.
	 */
	int_opp: opp-table-int {
		compatible = "operating-points-v2";
		opp-100000000 { opp-hz = /bits/ 64 <100000000>; opp-microvolt = <800000>; };
		opp-133000000 { opp-hz = /bits/ 64 <133000000>; opp-microvolt = <800000>; };
		opp-200000000 { opp-hz = /bits/ 64 <200000000>; opp-microvolt = <800000>; };
		opp-267000000 { opp-hz = /bits/ 64 <267000000>; opp-microvolt = <800000>; };
		opp-356000000 { opp-hz = /bits/ 64 <356000000>; opp-microvolt = <800000>; };
		opp-400000000 { opp-hz = /bits/ 64 <400000000>; opp-microvolt = <800000>; };
		opp-465000000 { opp-hz = /bits/ 64 <465000000>; opp-microvolt = <800000>; };
		opp-533000000 { opp-hz = /bits/ 64 <533000000>; opp-microvolt = <800000>; };
	};

	bus_int: bus-int {
		compatible = "samsung,exynos-bus";
		clocks = <&acpm_ipc GS201_CLK_ACPM_DVFS_INT>;
		clock-names = "bus";
		operating-points-v2 = <&int_opp>;
		vdd-supply = <&mif_dummy_vdd>;
		/* Passive: track bus_mif (the DRAM-side load proxy). */
		devfreq = <&bus_mif>;
		/*
		 * Source interconnect node for the GPU path; links up to bus_mif
		 * (the DMC). ratio 8 => a peak-kBps vote maps to kHz/8; INT clamps
		 * it to its own 533MHz max, so any GPU vote pulls INT toward max.
		 */
		#interconnect-cells = <0>;
		interconnects = <&bus_mif>;
		samsung,data-clock-ratio = <8>;
	};
};
